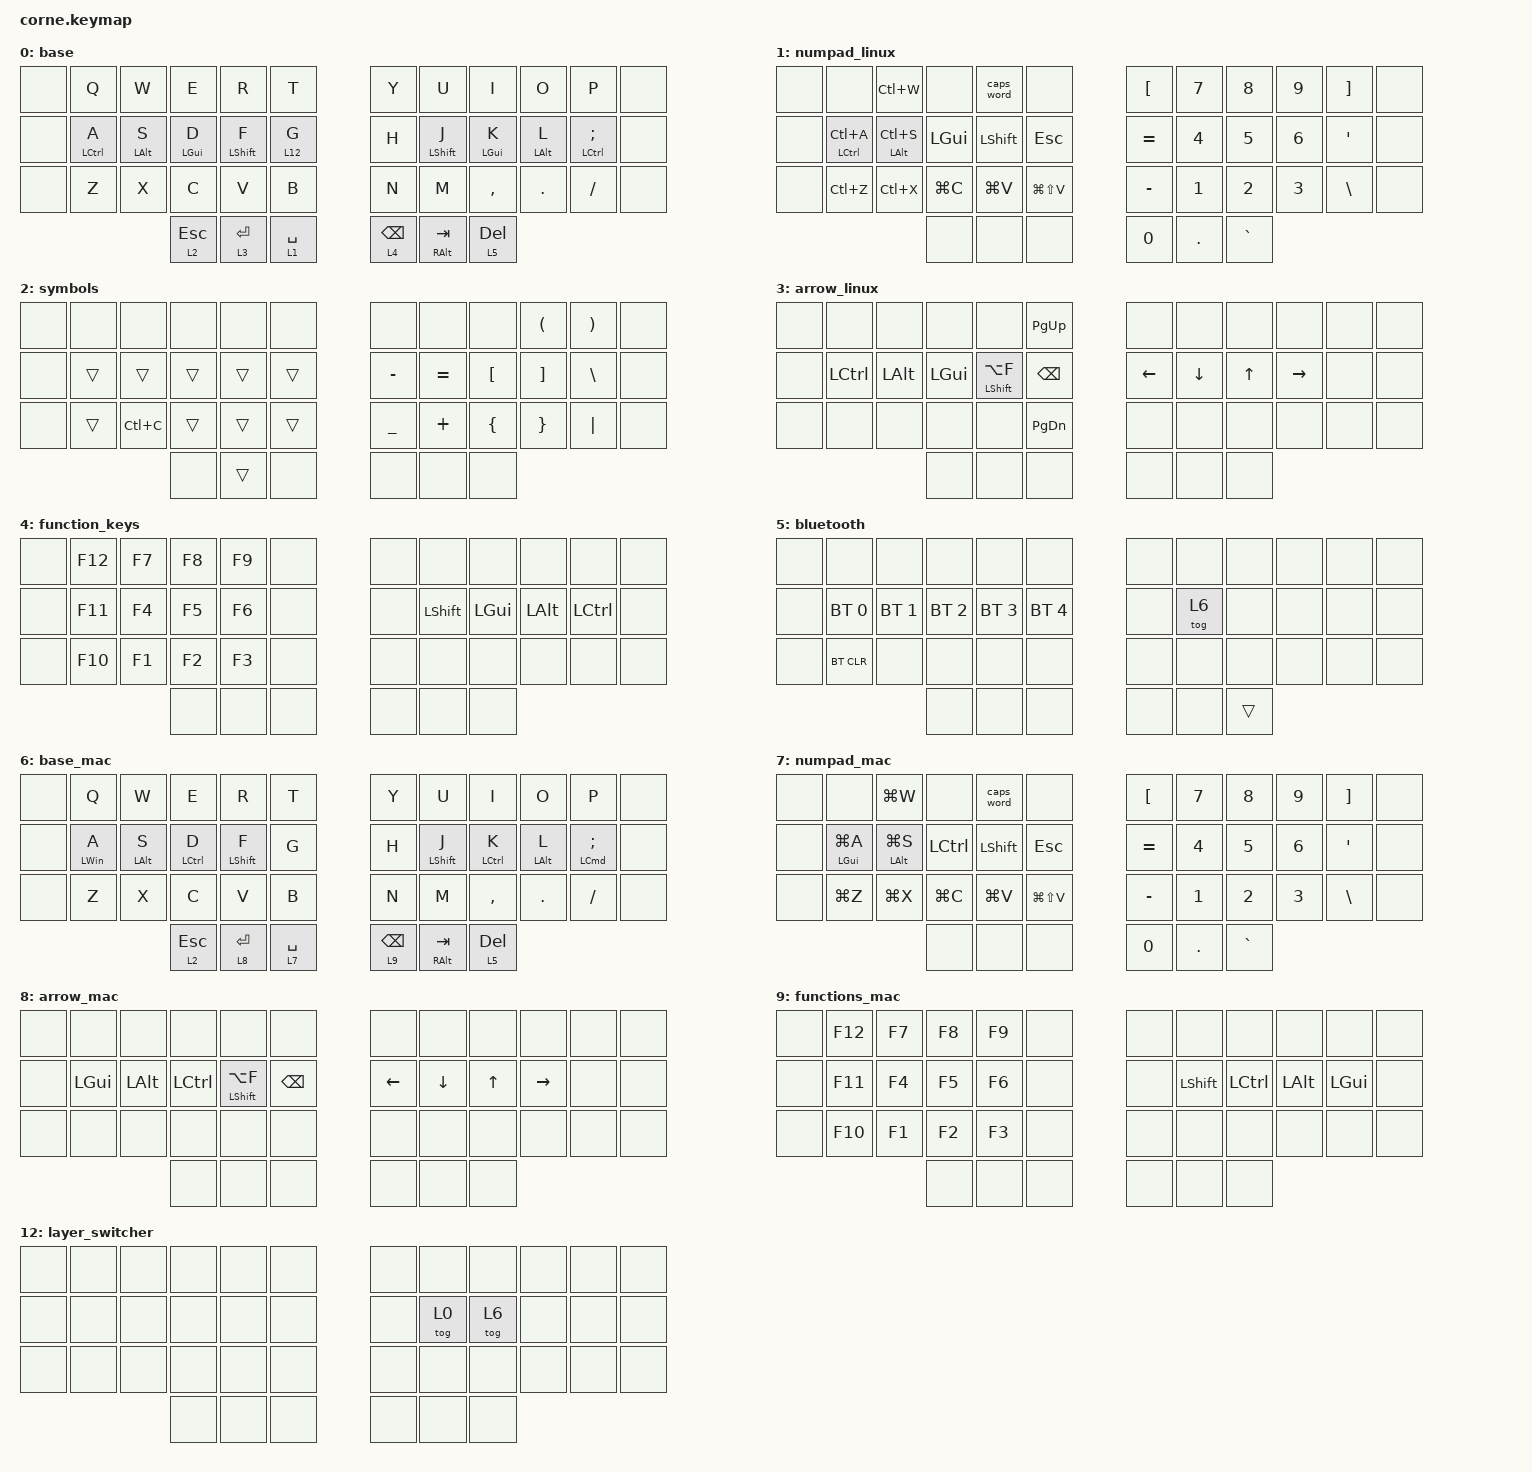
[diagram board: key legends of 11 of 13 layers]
/*
 * Copyright (c) 2020 The ZMK Contributors
 *
 * SPDX-License-Identifier: MIT
 */

#include <behaviors.dtsi>
#include <dt-bindings/zmk/bt.h>
#include <dt-bindings/zmk/keys.h>

&mt {
    flavor = "balanced";
    tapping-term-ms = <150>;
};

&lt { flavor = "hold-preferred"; };

/ {
    keymap {
        compatible = "zmk,keymap";

        base {
            // -----------------------------------------------------------------------------------------
            // |  TAB |  Q  |  W  |  E  |  R  |  T  |   |  Y  |  U   |  I  |  O  |  P  | BKSP |
            // | CTRL |  A  |  S  |  D  |  F  |  G  |   |  H  |  J   |  K  |  L  |  ;  |  '   |
            // | SHFT |  Z  |  X  |  C  |  V  |  B  |   |  N  |  M   |  ,  |  .  |  /  | ESC  |
            //                    | GUI | LWR | SPC |   | ENT | RSE  | ALT |

            bindings = <
&none  &kp Q        &kp W       &kp E           &kp R             &kp T          &kp Y            &kp U             &kp I         &kp O           &kp P           &none
&none  &mt LCTRL A  &mt LALT S  &mt LEFT_GUI D  &mt LEFT_SHIFT F  &lt 12 G       &kp H            &mt LEFT_SHIFT J  &mt LGUI K    &mt LEFT_ALT L  &mt LCTRL SEMI  &none
&none  &kp Z        &kp X       &kp C           &kp V             &kp B          &kp N            &kp M             &kp COMMA     &kp DOT         &kp FSLH        &none
                                &lt 2 ESC       &lt 3 ENTER       &lt 1 SPACE    &lt 4 BACKSPACE  &mt RALT TAB      &lt 5 DELETE
            >;
        };

        numpad_linux {
            bindings = <
&none  &none            &kp LC(W)       &none      &caps_word  &none            &kp LBKT   &kp N7   &kp N8     &kp N9  &kp RBKT  &none
&none  &mt LCTRL LC(A)  &mt LALT LC(S)  &kp LGUI   &kp LSHFT   &kp ESC          &kp EQUAL  &kp N4   &kp N5     &kp N6  &kp SQT   &none
&none  &kp LC(Z)        &kp LC(X)       &kp LG(C)  &kp LG(V)   &kp LG(LS(V))    &kp MINUS  &kp N1   &kp N2     &kp N3  &kp BSLH  &none
                                        &none      &none       &none            &kp N0     &kp DOT  &kp GRAVE
            >;
        };

        symbols {
            // -----------------------------------------------------------------------------------------
            // |  TAB |  1  |  2  |  3  |  4  |  5  |   |  6  |  7  |  8  |  9  |  0  | BKSP |
            // | BTCLR| BT1 | BT2 | BT3 | BT4 | BT5 |   | LFT | DWN |  UP | RGT |     |      |
            // | SHFT |     |     |     |     |     |   |     |     |     |     |     |      |
            //                    | GUI |     | SPC |   | ENT |     | ALT |

            bindings = <
&none  &none   &none      &none   &none   &none     &none      &none      &none     &kp LPAR  &kp RPAR  &none
&none  &trans  &trans     &trans  &trans  &trans    &kp MINUS  &kp EQUAL  &kp LBKT  &kp RBKT  &kp BSLH  &none
&none  &trans  &kp LC(C)  &trans  &trans  &trans    &kp UNDER  &kp PLUS   &kp LBRC  &kp RBRC  &kp PIPE  &none
                          &none   &trans  &none     &none      &none      &none
            >;
        };

        arrow_linux {
            bindings = <
&none  &none      &none     &none     &none                 &kp PG_UP        &none     &none     &none   &none      &none  &none
&none  &kp LCTRL  &kp LALT  &kp LGUI  &mt LEFT_SHIFT LA(F)  &kp BSPC         &kp LEFT  &kp DOWN  &kp UP  &kp RIGHT  &none  &none
&none  &none      &none     &none     &none                 &kp PAGE_DOWN    &none     &none     &none   &none      &none  &none
                            &none     &none                 &none            &none     &none     &none
            >;
        };

        function_keys {
            bindings = <
&none  &kp F12  &kp F7  &kp F8  &kp F9  &none    &none  &none           &none     &none     &none             &none
&none  &kp F11  &kp F4  &kp F5  &kp F6  &none    &none  &kp LEFT_SHIFT  &kp LGUI  &kp LALT  &kp LEFT_CONTROL  &none
&none  &kp F10  &kp F1  &kp F2  &kp F3  &none    &none  &none           &none     &none     &none             &none
                        &none   &none   &none    &none  &none           &none
            >;
        };

        bluetooth {
            bindings = <
&none  &none         &none         &none         &none         &none           &none  &none   &none   &none  &none  &none
&none  &bt BT_SEL 0  &bt BT_SEL 1  &bt BT_SEL 2  &bt BT_SEL 3  &bt BT_SEL 4    &none  &tog 6  &none   &none  &none  &none
&none  &bt BT_CLR    &none         &none         &none         &none           &none  &none   &none   &none  &none  &none
                                   &none         &none         &none           &none  &none   &trans
            >;
        };

        base_mac {
            bindings = <
&none  &kp Q       &kp W       &kp E        &kp R             &kp T          &kp Y            &kp U             &kp I         &kp O           &kp P                  &none
&none  &mt LWIN A  &mt LALT S  &mt LCTRL D  &mt LEFT_SHIFT F  &kp G          &kp H            &mt LEFT_SHIFT J  &mt LCTRL K   &mt LEFT_ALT L  &mt LEFT_COMMAND SEMI  &none
&none  &kp Z       &kp X       &kp C        &kp V             &kp B          &kp N            &kp M             &kp COMMA     &kp DOT         &kp FSLH               &none
                               &lt 2 ESC    &lt 8 ENTER       &lt 7 SPACE    &lt 9 BACKSPACE  &mt RALT TAB      &lt 5 DELETE
            >;
        };

        numpad_mac {
            bindings = <
&none  &none           &kp LG(W)       &none      &caps_word  &none            &kp LBKT   &kp N7   &kp N8     &kp N9  &kp RBKT  &none
&none  &mt LGUI LG(A)  &mt LALT LG(S)  &kp LCTRL  &kp LSHFT   &kp ESC          &kp EQUAL  &kp N4   &kp N5     &kp N6  &kp SQT   &none
&none  &kp LG(Z)       &kp LG(X)       &kp LG(C)  &kp LG(V)   &kp LG(LS(V))    &kp MINUS  &kp N1   &kp N2     &kp N3  &kp BSLH  &none
                                       &none      &none       &none            &kp N0     &kp DOT  &kp GRAVE
            >;
        };

        arrow_mac {
            bindings = <
&none  &none     &none     &none      &none                 &none       &none     &none     &none   &none      &none  &none
&none  &kp LGUI  &kp LALT  &kp LCTRL  &mt LEFT_SHIFT LA(F)  &kp BSPC    &kp LEFT  &kp DOWN  &kp UP  &kp RIGHT  &none  &none
&none  &none     &none     &none      &none                 &none       &none     &none     &none   &none      &none  &none
                           &none      &none                 &none       &none     &none     &none
            >;
        };

        functions_mac {
            bindings = <
&none  &kp F12  &kp F7  &kp F8  &kp F9  &none    &none  &none           &none      &none     &none         &none
&none  &kp F11  &kp F4  &kp F5  &kp F6  &none    &none  &kp LEFT_SHIFT  &kp LCTRL  &kp LALT  &kp LEFT_GUI  &none
&none  &kp F10  &kp F1  &kp F2  &kp F3  &none    &none  &none           &none      &none     &none         &none
                        &none   &none   &none    &none  &none           &none
            >;
        };

        Hyper {
            bindings = <
&none  &none  &none  &none                  &none                  &none    &none                     &none                     &none                   &none                      &none  &none
&none  &none  &none  &kp LS(LA(LC(LG(D))))  &kp LS(LA(LC(LG(F))))  &none    &kp LS(LA(LC(LG(LEFT))))  &kp LS(LA(LG(LC(DOWN))))  &kp LS(LA(LC(LG(UP))))  &kp LS(LA(LC(LG(RIGHT))))  &none  &none
&none  &none  &none  &none                  &none                  &none    &none                     &none                     &none                   &none                      &none  &none
                     &none                  &none                  &none    &none                     &none                     &none
            >;
        };

        win-manager {
            bindings = <
&none  &none  &none  &none  &none                  &none    &none  &none  &none  &none  &none  &none
&none  &none  &none  &none  &kp LS(LA(LC(LG(F))))  &none    &none  &none  &none  &none  &none  &none
&none  &none  &none  &none  &none                  &none    &none  &none  &none  &none  &none  &none
                     &none  &none                  &none    &none  &none  &none
            >;
        };

        layer_switcher {
            bindings = <
&none  &none  &none  &none  &none  &none    &none  &none   &none   &none  &none  &none
&none  &none  &none  &none  &none  &none    &none  &tog 0  &tog 6  &none  &none  &none
&none  &none  &none  &none  &none  &none    &none  &none   &none   &none  &none  &none
                     &none  &none  &none    &none  &none   &none
            >;
        };
    };
};
